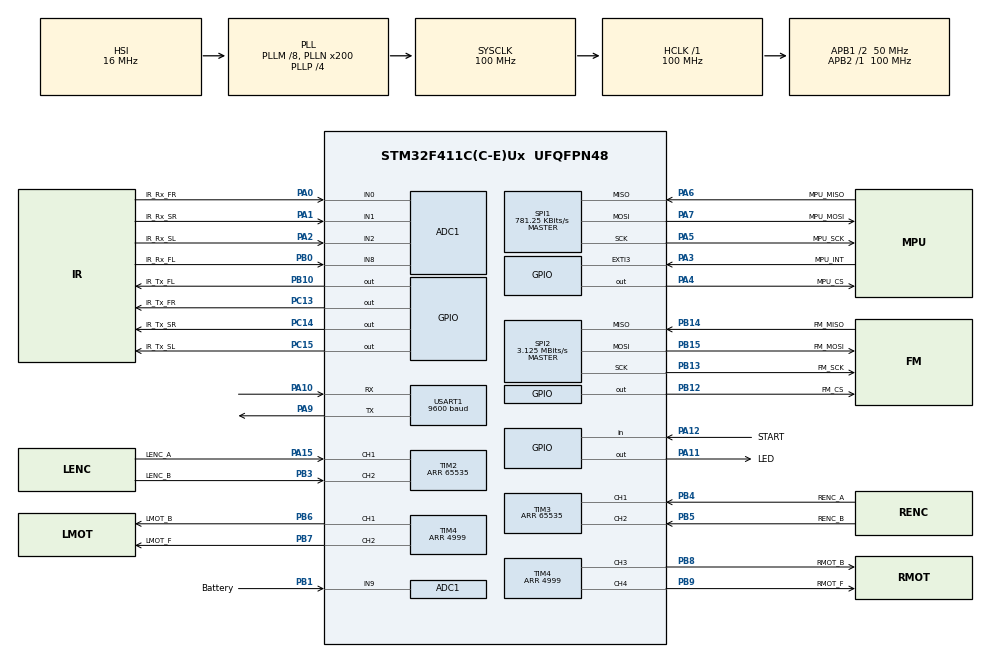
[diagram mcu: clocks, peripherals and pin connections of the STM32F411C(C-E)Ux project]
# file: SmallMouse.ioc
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ADC1.Channel-0\#ChannelRegularConversion=ADC_CHANNEL_8
ADC1.Channel-1\#ChannelRegularConversion=ADC_CHANNEL_1
ADC1.Channel-2\#ChannelRegularConversion=ADC_CHANNEL_2
ADC1.Channel-3\#ChannelRegularConversion=ADC_CHANNEL_0
ADC1.Channel-4\#ChannelRegularConversion=ADC_CHANNEL_9
ADC1.ContinuousConvMode=ENABLE
ADC1.DMAContinuousRequests=ENABLE
ADC1.EOCSelection=ADC_EOC_SEQ_CONV
ADC1.NbrOfConversion=5
ADC1.NbrOfConversionFlag=1
ADC1.Rank-0\#ChannelRegularConversion=1
ADC1.Rank-1\#ChannelRegularConversion=2
ADC1.Rank-2\#ChannelRegularConversion=3
ADC1.Rank-3\#ChannelRegularConversion=4
ADC1.Rank-4\#ChannelRegularConversion=5
ADC1.SamplingTime-0\#ChannelRegularConversion=ADC_SAMPLETIME_28CYCLES
ADC1.SamplingTime-1\#ChannelRegularConversion=ADC_SAMPLETIME_28CYCLES
ADC1.SamplingTime-2\#ChannelRegularConversion=ADC_SAMPLETIME_28CYCLES
ADC1.SamplingTime-3\#ChannelRegularConversion=ADC_SAMPLETIME_28CYCLES
ADC1.SamplingTime-4\#ChannelRegularConversion=ADC_SAMPLETIME_28CYCLES
ADC1.ScanConvMode=ENABLE
ADC1.master=1
Dma.ADC1.2.Direction=DMA_PERIPH_TO_MEMORY
Dma.ADC1.2.FIFOMode=DMA_FIFOMODE_DISABLE
Dma.ADC1.2.Instance=DMA2_Stream4
Dma.ADC1.2.MemDataAlignment=DMA_MDATAALIGN_HALFWORD
Dma.ADC1.2.MemInc=DMA_MINC_ENABLE
Dma.ADC1.2.Mode=DMA_CIRCULAR
Dma.ADC1.2.PeriphDataAlignment=DMA_PDATAALIGN_HALFWORD
Dma.ADC1.2.PeriphInc=DMA_PINC_DISABLE
Dma.ADC1.2.Priority=DMA_PRIORITY_LOW
Dma.Request0=USART1_RX
Dma.Request1=USART1_TX
Dma.Request2=ADC1
Dma.Request3=SPI1_RX
Dma.Request4=SPI1_TX
Dma.Request5=SPI2_RX
Dma.Request6=SPI2_TX
Dma.SPI1_RX.3.Direction=DMA_PERIPH_TO_MEMORY
Dma.SPI1_RX.3.FIFOMode=DMA_FIFOMODE_DISABLE
Dma.SPI1_RX.3.Instance=DMA2_Stream0
Dma.SPI1_RX.3.MemDataAlignment=DMA_MDATAALIGN_BYTE
Dma.SPI1_RX.3.MemInc=DMA_MINC_ENABLE
Dma.SPI1_RX.3.Mode=DMA_NORMAL
Dma.SPI1_RX.3.PeriphDataAlignment=DMA_PDATAALIGN_BYTE
Dma.SPI1_RX.3.PeriphInc=DMA_PINC_DISABLE
Dma.SPI1_RX.3.Priority=DMA_PRIORITY_LOW
Dma.SPI1_TX.4.Direction=DMA_MEMORY_TO_PERIPH
Dma.SPI1_TX.4.FIFOMode=DMA_FIFOMODE_DISABLE
Dma.SPI1_TX.4.Instance=DMA2_Stream3
Dma.SPI1_TX.4.MemDataAlignment=DMA_MDATAALIGN_BYTE
Dma.SPI1_TX.4.MemInc=DMA_MINC_ENABLE
Dma.SPI1_TX.4.Mode=DMA_NORMAL
Dma.SPI1_TX.4.PeriphDataAlignment=DMA_PDATAALIGN_BYTE
Dma.SPI1_TX.4.PeriphInc=DMA_PINC_DISABLE
Dma.SPI1_TX.4.Priority=DMA_PRIORITY_LOW
Dma.SPI2_RX.5.Direction=DMA_PERIPH_TO_MEMORY
Dma.SPI2_RX.5.FIFOMode=DMA_FIFOMODE_DISABLE
Dma.SPI2_RX.5.Instance=DMA1_Stream3
Dma.SPI2_RX.5.MemDataAlignment=DMA_MDATAALIGN_BYTE
Dma.SPI2_RX.5.MemInc=DMA_MINC_ENABLE
Dma.SPI2_RX.5.Mode=DMA_NORMAL
Dma.SPI2_RX.5.PeriphDataAlignment=DMA_PDATAALIGN_BYTE
Dma.SPI2_RX.5.PeriphInc=DMA_PINC_DISABLE
Dma.SPI2_RX.5.Priority=DMA_PRIORITY_LOW
Dma.SPI2_TX.6.Direction=DMA_MEMORY_TO_PERIPH
Dma.SPI2_TX.6.FIFOMode=DMA_FIFOMODE_DISABLE
Dma.SPI2_TX.6.Instance=DMA1_Stream4
Dma.SPI2_TX.6.MemDataAlignment=DMA_MDATAALIGN_BYTE
Dma.SPI2_TX.6.MemInc=DMA_MINC_ENABLE
Dma.SPI2_TX.6.Mode=DMA_NORMAL
Dma.SPI2_TX.6.PeriphDataAlignment=DMA_PDATAALIGN_BYTE
Dma.SPI2_TX.6.PeriphInc=DMA_PINC_DISABLE
Dma.SPI2_TX.6.Priority=DMA_PRIORITY_LOW
Dma.USART1_RX.0.Direction=DMA_PERIPH_TO_MEMORY
Dma.USART1_RX.0.FIFOMode=DMA_FIFOMODE_DISABLE
Dma.USART1_RX.0.Instance=DMA2_Stream2
Dma.USART1_RX.0.MemDataAlignment=DMA_MDATAALIGN_BYTE
Dma.USART1_RX.0.MemInc=DMA_MINC_ENABLE
Dma.USART1_RX.0.Mode=DMA_NORMAL
Dma.USART1_RX.0.PeriphDataAlignment=DMA_PDATAALIGN_BYTE
Dma.USART1_RX.0.PeriphInc=DMA_PINC_DISABLE
Dma.USART1_RX.0.Priority=DMA_PRIORITY_LOW
Dma.USART1_TX.1.Direction=DMA_MEMORY_TO_PERIPH
Dma.USART1_TX.1.FIFOMode=DMA_FIFOMODE_DISABLE
Dma.USART1_TX.1.Instance=DMA2_Stream7
Dma.USART1_TX.1.MemDataAlignment=DMA_MDATAALIGN_BYTE
Dma.USART1_TX.1.MemInc=DMA_MINC_ENABLE
Dma.USART1_TX.1.Mode=DMA_NORMAL
Dma.USART1_TX.1.PeriphDataAlignment=DMA_PDATAALIGN_BYTE
Dma.USART1_TX.1.PeriphInc=DMA_PINC_DISABLE
Dma.USART1_TX.1.Priority=DMA_PRIORITY_LOW
Mcu.Family=STM32F4
Mcu.Name=STM32F411C(C-E)Ux
Mcu.Package=UFQFPN48
NVIC.DMA1_Stream3_IRQn=true\:1\:0\:true\:false\:true\:false\:true
NVIC.DMA1_Stream4_IRQn=true\:1\:0\:true\:false\:true\:false\:true
NVIC.DMA2_Stream0_IRQn=true\:1\:0\:true\:false\:true\:false\:true
NVIC.DMA2_Stream2_IRQn=true\:1\:0\:true\:false\:true\:false\:true
NVIC.DMA2_Stream3_IRQn=true\:1\:0\:true\:false\:true\:false\:true
NVIC.DMA2_Stream4_IRQn=true\:1\:0\:true\:false\:true\:false\:true
NVIC.DMA2_Stream7_IRQn=true\:1\:0\:true\:false\:true\:false\:true
NVIC.EXTI3_IRQn=true\:2\:0\:true\:false\:true\:true\:true
NVIC.PriorityGroup=NVIC_PRIORITYGROUP_4
NVIC.SPI1_IRQn=true\:1\:0\:true\:false\:true\:true\:true
NVIC.SPI2_IRQn=true\:1\:0\:true\:false\:true\:true\:true
NVIC.TIM1_BRK_TIM9_IRQn=true\:1\:0\:true\:false\:true\:true\:true
NVIC.USART1_IRQn=true\:3\:0\:true\:false\:true\:true\:true
PA0-WKUP.GPIO_Label=IR_Rx_FR
PA0-WKUP.Signal=ADCx_IN0
PA1.GPIO_Label=IR_Rx_SR
PA1.Signal=ADCx_IN1
PA10.Mode=Asynchronous
PA10.Signal=USART1_RX
PA11.GPIO_Label=LED
PA11.Signal=GPIO_Output
PA12.GPIO_Label=START
PA12.Signal=GPIO_Input
PA13.Mode=Serial_Wire
PA13.Signal=SYS_JTMS-SWDIO
PA14.Mode=Serial_Wire
PA14.Signal=SYS_JTCK-SWCLK
PA15.GPIO_Label=LENC_A
PA15.Signal=S_TIM2_CH1_ETR
PA2.GPIO_Label=IR_Rx_SL
PA2.Signal=ADCx_IN2
PA3.GPIO_Label=MPU_INT
PA3.GPIO_ModeDefaultEXTI=GPIO_MODE_IT_FALLING
PA3.Signal=GPXTI3
PA4.GPIO_Label=MPU_CS
PA4.Signal=GPIO_Output
PA5.GPIO_Label=MPU_SCK
PA5.Mode=Full_Duplex_Master
PA5.Signal=SPI1_SCK
PA6.GPIO_Label=MPU_MISO
PA6.Mode=Full_Duplex_Master
PA6.Signal=SPI1_MISO
PA7.GPIO_Label=MPU_MOSI
PA7.Mode=Full_Duplex_Master
PA7.Signal=SPI1_MOSI
PA9.Mode=Asynchronous
PA9.Signal=USART1_TX
PB0.GPIO_Label=IR_Rx_FL
PB0.Signal=ADCx_IN8
PB1.GPIO_Label=Battery
PB1.Signal=ADCx_IN9
PB10.GPIO_Label=IR_Tx_FL
PB10.Signal=GPIO_Output
PB12.GPIO_Label=FM_CS
PB12.Signal=GPIO_Output
PB13.GPIO_Label=FM_SCK
PB13.Mode=Full_Duplex_Master
PB13.Signal=SPI2_SCK
PB14.GPIO_Label=FM_MISO
PB14.Mode=Full_Duplex_Master
PB14.Signal=SPI2_MISO
PB15.GPIO_Label=FM_MOSI
PB15.Mode=Full_Duplex_Master
PB15.Signal=SPI2_MOSI
PB3.GPIO_Label=LENC_B
PB3.Signal=S_TIM2_CH2
PB4.GPIO_Label=RENC_A
PB4.Signal=S_TIM3_CH1
PB5.GPIO_Label=RENC_B
PB5.Signal=S_TIM3_CH2
PB6.GPIO_Label=LMOT_B
PB6.Signal=S_TIM4_CH1
PB7.GPIO_Label=LMOT_F
PB7.Signal=S_TIM4_CH2
PB8.GPIO_Label=RMOT_B
PB8.Signal=S_TIM4_CH3
PB9.GPIO_Label=RMOT_F
PB9.Signal=S_TIM4_CH4
PC13-ANTI_TAMP.GPIO_Label=IR_Tx_FR
PC13-ANTI_TAMP.Signal=GPIO_Output
PC14-OSC32_IN.GPIO_Label=IR_Tx_SR
PC14-OSC32_IN.Signal=GPIO_Output
PC15-OSC32_OUT.GPIO_Label=IR_Tx_SL
PC15-OSC32_OUT.Signal=GPIO_Output
ProjectManager.HeapSize=0x2000
ProjectManager.StackSize=0x4000
ProjectManager.TargetToolchain=MDK-ARM V5.27
RCC.48MHZClocksFreq_Value=100000000
RCC.AHBFreq_Value=100000000
RCC.APB1CLKDivider=RCC_HCLK_DIV2
RCC.APB1Freq_Value=50000000
RCC.APB1TimFreq_Value=100000000
RCC.APB2Freq_Value=100000000
RCC.APB2TimFreq_Value=100000000
RCC.CortexFreq_Value=100000000
RCC.HCLKFreq_Value=100000000
RCC.HSE_VALUE=8000000
RCC.HSI_VALUE=16000000
RCC.LSE_VALUE=32768
RCC.PLLM=8
RCC.PLLN=200
RCC.PLLP=RCC_PLLP_DIV4
RCC.SYSCLKFreq_VALUE=100000000
RCC.SYSCLKSource=RCC_SYSCLKSOURCE_PLLCLK
RCC.VCOOutputFreq_Value=400000000
SH.ADCx_IN0.0=ADC1_IN0,IN0
SH.ADCx_IN1.0=ADC1_IN1,IN1
SH.ADCx_IN2.0=ADC1_IN2,IN2
SH.ADCx_IN8.0=ADC1_IN8,IN8
SH.ADCx_IN9.0=ADC1_IN9,IN9
SH.S_TIM2_CH1_ETR.0=TIM2_CH1,Encoder_Interface
SH.S_TIM2_CH2.0=TIM2_CH2,Encoder_Interface
SH.S_TIM3_CH1.0=TIM3_CH1,Encoder_Interface
SH.S_TIM3_CH2.0=TIM3_CH2,Encoder_Interface
SH.S_TIM4_CH1.0=TIM4_CH1,PWM Generation1 CH1
SH.S_TIM4_CH2.0=TIM4_CH2,PWM Generation2 CH2
SH.S_TIM4_CH3.0=TIM4_CH3,PWM Generation3 CH3
SH.S_TIM4_CH4.0=TIM4_CH4,PWM Generation4 CH4
SPI1.BaudRatePrescaler=SPI_BAUDRATEPRESCALER_128
SPI1.CalculateBaudRate=781.25 KBits/s
SPI1.Direction=SPI_DIRECTION_2LINES
SPI1.Mode=SPI_MODE_MASTER
SPI1.VirtualType=VM_MASTER
SPI2.BaudRatePrescaler=SPI_BAUDRATEPRESCALER_16
SPI2.CLKPhase=SPI_PHASE_1EDGE
SPI2.CalculateBaudRate=3.125 MBits/s
SPI2.DataSize=SPI_DATASIZE_8BIT
SPI2.Direction=SPI_DIRECTION_2LINES
SPI2.Mode=SPI_MODE_MASTER
SPI2.VirtualType=VM_MASTER
TIM2.EncoderMode=TIM_ENCODERMODE_TI12
TIM2.IC1Filter=6
TIM2.IC2Filter=6
TIM2.Period=65535
TIM3.EncoderMode=TIM_ENCODERMODE_TI12
TIM3.IC1Filter=6
TIM3.IC2Filter=6
TIM3.Period=65535
TIM4.Channel-PWM\ Generation1\ CH1=TIM_CHANNEL_1
TIM4.Channel-PWM\ Generation2\ CH2=TIM_CHANNEL_2
TIM4.Channel-PWM\ Generation3\ CH3=TIM_CHANNEL_3
TIM4.Channel-PWM\ Generation4\ CH4=TIM_CHANNEL_4
TIM4.OCMode_PWM-PWM\ Generation1\ CH1=TIM_OCMODE_PWM2
TIM4.OCMode_PWM-PWM\ Generation2\ CH2=TIM_OCMODE_PWM2
TIM4.OCMode_PWM-PWM\ Generation3\ CH3=TIM_OCMODE_PWM2
TIM4.OCMode_PWM-PWM\ Generation4\ CH4=TIM_OCMODE_PWM2
TIM4.Period=4999
TIM9.Period=249
TIM9.Prescaler=49
USART1.BaudRate=9600
USART1.VirtualMode=VM_ASYNC
VP_TIM4_VS_ClockSourceINT.Mode=Internal
VP_TIM9_VS_ClockSourceINT.Mode=Internal
board=custom

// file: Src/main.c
/* USER CODE BEGIN Header */
/**
  ******************************************************************************
  * @file           : main.c
  * @brief          : Main program body
  ******************************************************************************
  * @attention
  *
  * <h2><center>&copy; Copyright (c) 2019 STMicroelectronics.
  * All rights reserved.</center></h2>
  *
  * This software component is licensed by ST under BSD 3-Clause license,
  * the "License"; You may not use this file except in compliance with the
  * License. You may obtain a copy of the License at:
  *                        opensource.org/licenses/BSD-3-Clause
  *
  ******************************************************************************
  */
/* USER CODE END Header */

#include "main.h"
#include "adc.h"
#include "dma.h"
#include "spi.h"
#include "tim.h"
#include "usart.h"
#include "gpio.h"

/* USER CODE BEGIN Includes */
#include "modbus.h"
#include "mouse.h"
#include "maze.h"
/* USER CODE END Includes */

void SystemClock_Config(void);

int main(void)
{

  /* MCU Configuration--------------------------------------------------------*/

  /* Reset of all peripherals, Initializes the Flash interface and the Systick. */
  HAL_Init();

  /* Configure the system clock */
  SystemClock_Config();

  /* Initialize all configured peripherals */
  MX_GPIO_Init();
  MX_DMA_Init();
  MX_ADC1_Init();
  MX_SPI1_Init();
  MX_SPI2_Init();
  MX_TIM4_Init();
  MX_TIM9_Init();
  MX_USART1_UART_Init();
  MX_TIM2_Init();
  MX_TIM3_Init();
  /* USER CODE BEGIN 2 */

	mouseInit();

  /* USER CODE END 2 */

  /* Infinite loop */
  while (1)
  {

    /* USER CODE BEGIN 3 */
		mainTask();
		modbusProcess();
  }
  /* USER CODE END 3 */
}

void SystemClock_Config(void)
{
  RCC_OscInitTypeDef RCC_OscInitStruct = {0};
  RCC_ClkInitTypeDef RCC_ClkInitStruct = {0};

  /** Configure the main internal regulator output voltage
  */
  __HAL_RCC_PWR_CLK_ENABLE();
  __HAL_PWR_VOLTAGESCALING_CONFIG(PWR_REGULATOR_VOLTAGE_SCALE1);
  /** Initializes the CPU, AHB and APB busses clocks
  */
  RCC_OscInitStruct.OscillatorType = RCC_OSCILLATORTYPE_HSI;
  RCC_OscInitStruct.HSIState = RCC_HSI_ON;
  RCC_OscInitStruct.HSICalibrationValue = RCC_HSICALIBRATION_DEFAULT;
  RCC_OscInitStruct.PLL.PLLState = RCC_PLL_ON;
  RCC_OscInitStruct.PLL.PLLSource = RCC_PLLSOURCE_HSI;
  RCC_OscInitStruct.PLL.PLLM = 8;
  RCC_OscInitStruct.PLL.PLLN = 200;
  RCC_OscInitStruct.PLL.PLLP = RCC_PLLP_DIV4;
  RCC_OscInitStruct.PLL.PLLQ = 4;
  if (HAL_RCC_OscConfig(&RCC_OscInitStruct) != HAL_OK)
  {
    Error_Handler();
  }
  /** Initializes the CPU, AHB and APB busses clocks
  */
  RCC_ClkInitStruct.ClockType = RCC_CLOCKTYPE_HCLK|RCC_CLOCKTYPE_SYSCLK
                              |RCC_CLOCKTYPE_PCLK1|RCC_CLOCKTYPE_PCLK2;
  RCC_ClkInitStruct.SYSCLKSource = RCC_SYSCLKSOURCE_PLLCLK;
  RCC_ClkInitStruct.AHBCLKDivider = RCC_SYSCLK_DIV1;
  RCC_ClkInitStruct.APB1CLKDivider = RCC_HCLK_DIV2;
  RCC_ClkInitStruct.APB2CLKDivider = RCC_HCLK_DIV1;

  if (HAL_RCC_ClockConfig(&RCC_ClkInitStruct, FLASH_LATENCY_3) != HAL_OK)
  {
    Error_Handler();
  }
}

void Error_Handler(void)
{
}

/************************ (C) COPYRIGHT STMicroelectronics *****END OF FILE****/
